# PIC32MZ2048EFM144 register map
Registers are 32-bit, access not given, reset 0x0 unless marked. A register's access mark holds for its fields unless they carry their own. Offsets are from the block's base; [hi:lo] are bit positions; {n}, {i} and the like mark numbered series; 'fields as' and 'values as' point back to an identical list.

## CFG — CFG peripheral
Base 0xBF800000
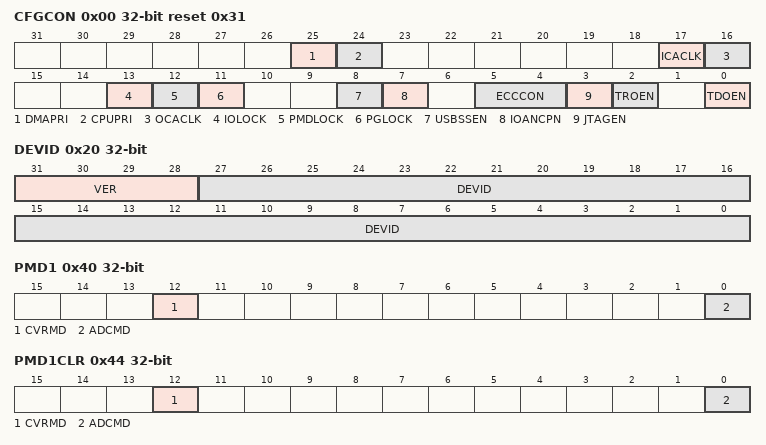
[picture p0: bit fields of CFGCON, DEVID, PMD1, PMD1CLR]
0x00 CFGCON reset 0x31
  [25] DMAPRI, [24] CPUPRI, [17] ICACLK, [16] OCACLK, [13] IOLOCK, [12] PMDLOCK, [11] PGLOCK, [8] USBSSEN, [7] IOANCPN, [5:4] ECCCON, [3] JTAGEN, [2] TROEN, [0] TDOEN
0x20 DEVID
  [31:28] VER, [27:0] DEVID
0x30 SYSKEY
0x40 PMD1
  [12] CVRMD, [0] ADCMD
0x44 PMD1CLR
  [12] CVRMD, [0] ADCMD
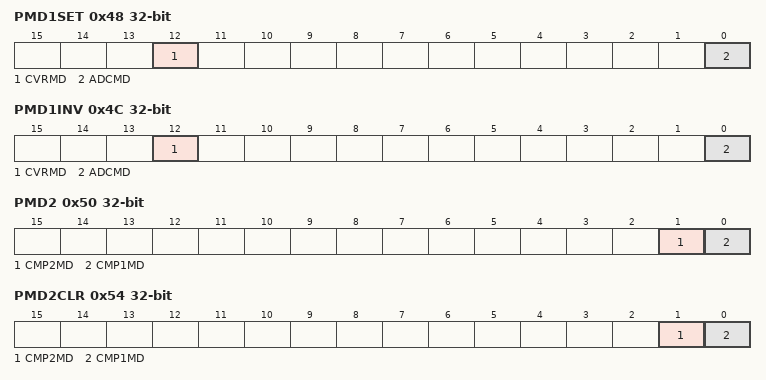
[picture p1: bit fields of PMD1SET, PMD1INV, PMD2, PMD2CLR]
0x48 PMD1SET
  [12] CVRMD, [0] ADCMD
0x4C PMD1INV
  [12] CVRMD, [0] ADCMD
0x50 PMD2
  [1] CMP2MD, [0] CMP1MD
0x54 PMD2CLR
  [1] CMP2MD, [0] CMP1MD
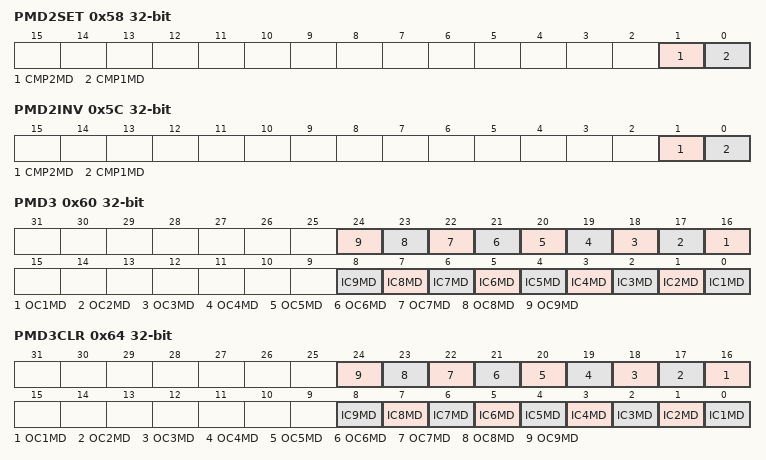
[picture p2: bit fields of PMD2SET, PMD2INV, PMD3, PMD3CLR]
0x58 PMD2SET
  [1] CMP2MD, [0] CMP1MD
0x5C PMD2INV
  [1] CMP2MD, [0] CMP1MD
0x60 PMD3
  [n+15] OC{n}MD (n=1..9), [n-1] IC{n}MD (n=1..9)
0x64 PMD3CLR
  [n+15] OC{n}MD (n=1..9), [n-1] IC{n}MD (n=1..9)
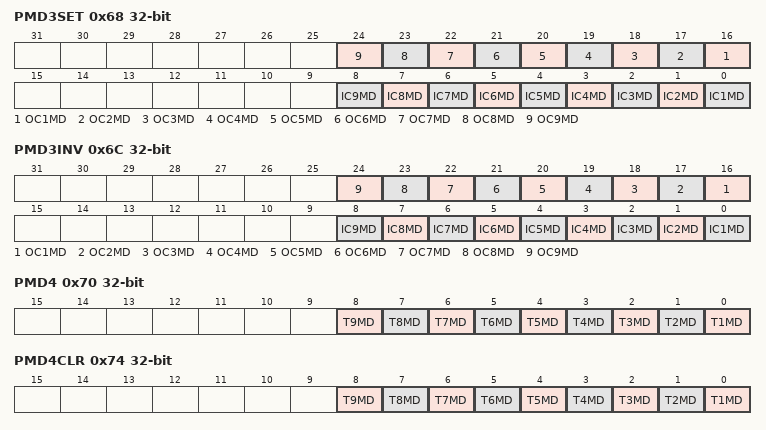
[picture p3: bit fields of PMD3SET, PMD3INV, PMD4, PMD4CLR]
0x68 PMD3SET
  [n+15] OC{n}MD (n=1..9), [n-1] IC{n}MD (n=1..9)
0x6C PMD3INV
  [n+15] OC{n}MD (n=1..9), [n-1] IC{n}MD (n=1..9)
0x70 PMD4
  [n-1] T{n}MD (n=1..9)
0x74 PMD4CLR
  [n-1] T{n}MD (n=1..9)
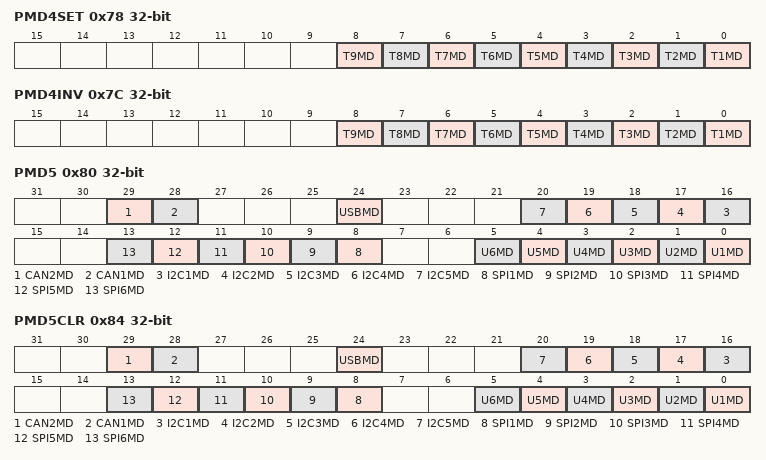
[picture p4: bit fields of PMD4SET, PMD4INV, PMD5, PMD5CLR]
0x78 PMD4SET
  [n-1] T{n}MD (n=1..9)
0x7C PMD4INV
  [n-1] T{n}MD (n=1..9)
0x80 PMD5
  [29] CAN2MD, [28] CAN1MD, [24] USBMD, [n+15] I2C{n}MD (n=1..5), [n+7] SPI{n}MD (n=1..6), [n-1] U{n}MD (n=1..6)
0x84 PMD5CLR
  fields as PMD5
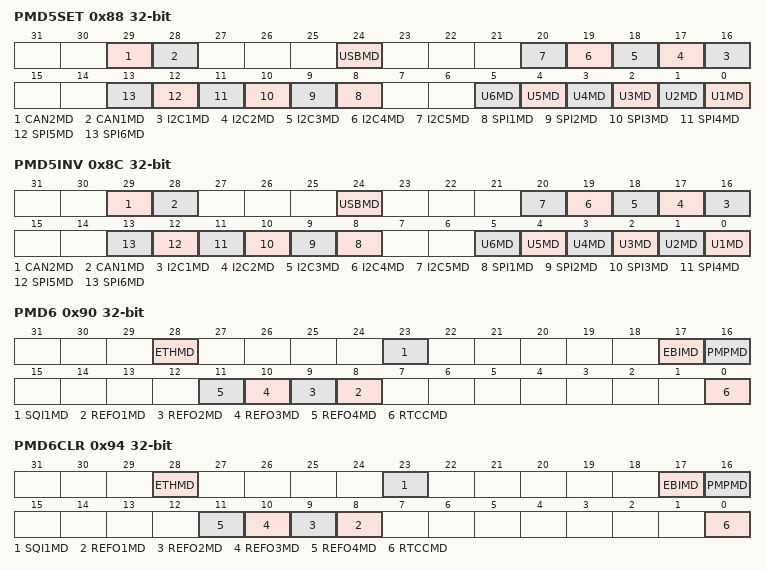
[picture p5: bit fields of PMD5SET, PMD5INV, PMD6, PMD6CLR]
0x88 PMD5SET
  fields as PMD5
0x8C PMD5INV
  fields as PMD5
0x90 PMD6
  [28] ETHMD, [23] SQI1MD, [17] EBIMD, [16] PMPMD, [n+7] REFO{n}MD (n=1..4), [0] RTCCMD
0x94 PMD6CLR
  fields as PMD6
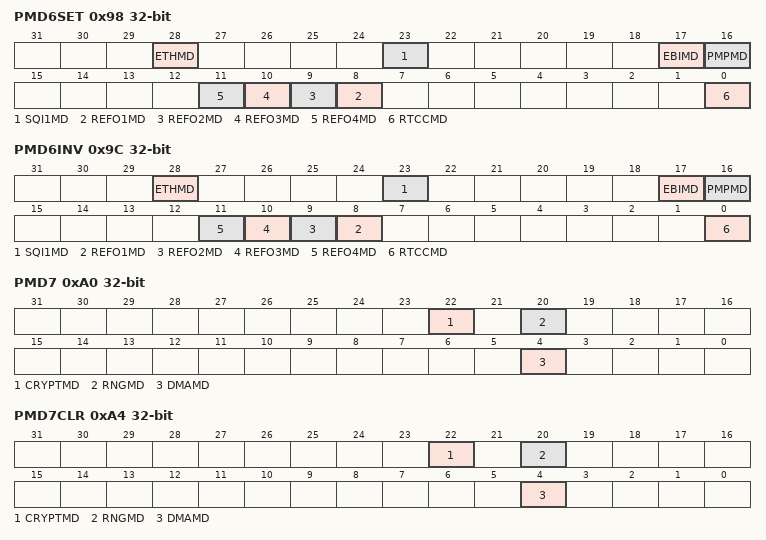
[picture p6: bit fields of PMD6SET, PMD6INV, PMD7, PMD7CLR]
0x98 PMD6SET
  fields as PMD6
0x9C PMD6INV
  fields as PMD6
0xA0 PMD7
  [22] CRYPTMD, [20] RNGMD, [4] DMAMD
0xA4 PMD7CLR
  [22] CRYPTMD, [20] RNGMD, [4] DMAMD
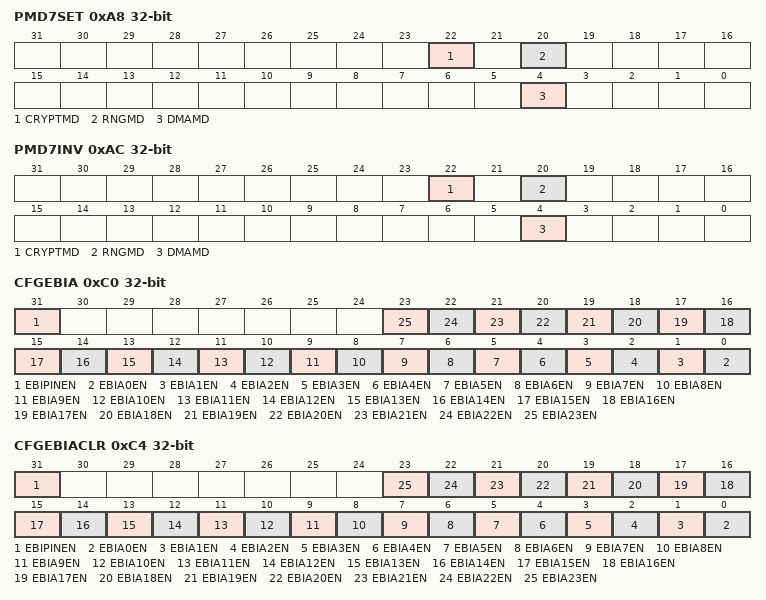
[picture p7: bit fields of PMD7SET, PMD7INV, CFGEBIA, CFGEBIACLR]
0xA8 PMD7SET
  [22] CRYPTMD, [20] RNGMD, [4] DMAMD
0xAC PMD7INV
  [22] CRYPTMD, [20] RNGMD, [4] DMAMD
0xC0 CFGEBIA
  [31] EBIPINEN, [n] EBIA{n}EN (n=0..23)
0xC4 CFGEBIACLR
  [31] EBIPINEN, [n] EBIA{n}EN (n=0..23)
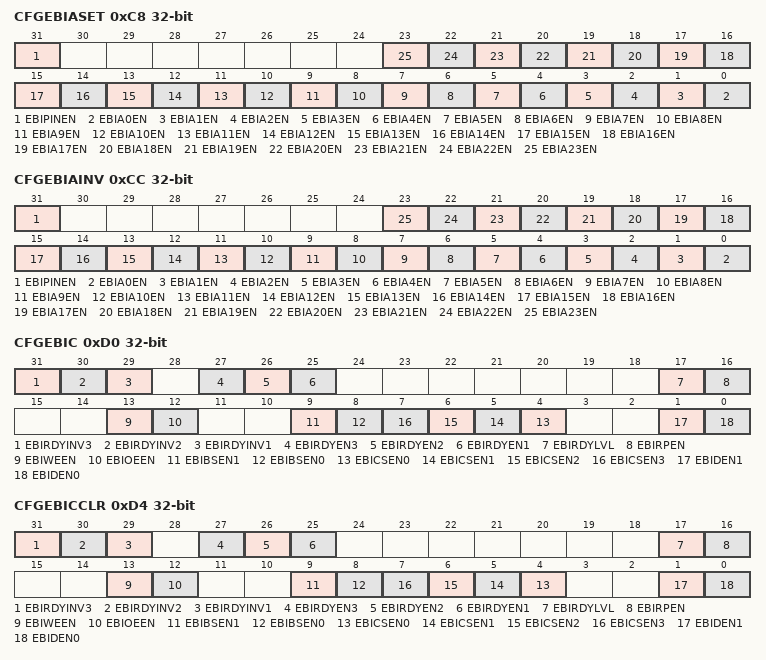
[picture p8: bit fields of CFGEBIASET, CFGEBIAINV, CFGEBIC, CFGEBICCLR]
0xC8 CFGEBIASET
  [31] EBIPINEN, [n] EBIA{n}EN (n=0..23)
0xCC CFGEBIAINV
  [31] EBIPINEN, [n] EBIA{n}EN (n=0..23)
0xD0 CFGEBIC
  [31] EBIRDYINV3, [30] EBIRDYINV2, [29] EBIRDYINV1, [27] EBIRDYEN3, [26] EBIRDYEN2, [25] EBIRDYEN1, [17] EBIRDYLVL, [16] EBIRPEN, [13] EBIWEEN, [12] EBIOEEN, [9] EBIBSEN1, [8] EBIBSEN0, [n+4] EBICSEN{n} (n=0..3), [1] EBIDEN1, [0] EBIDEN0
0xD4 CFGEBICCLR
  fields as CFGEBIC
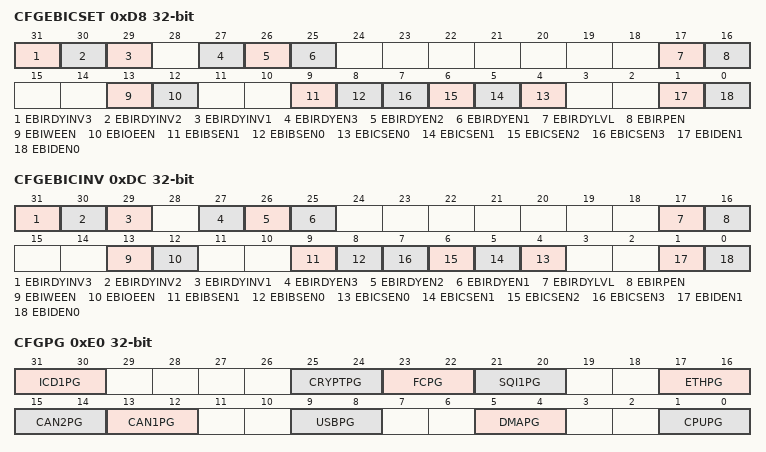
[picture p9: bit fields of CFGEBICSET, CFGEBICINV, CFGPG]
0xD8 CFGEBICSET
  fields as CFGEBIC
0xDC CFGEBICINV
  fields as CFGEBIC
0xE0 CFGPG
  [31:30] ICD1PG, [25:24] CRYPTPG, [23:22] FCPG, [21:20] SQI1PG, [17:16] ETHPG, [15:14] CAN2PG, [13:12] CAN1PG, [9:8] USBPG, [5:4] DMAPG, [1:0] CPUPG

## NVM — NVM peripheral
Base 0xBF800600
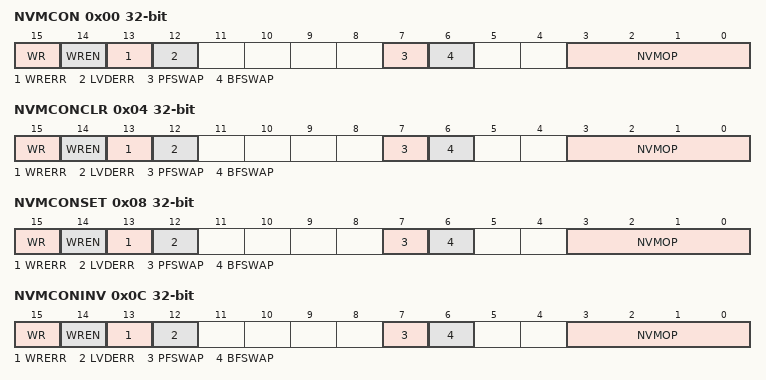
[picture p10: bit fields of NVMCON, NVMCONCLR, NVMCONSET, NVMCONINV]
0x00 NVMCON
  [15] WR, [14] WREN, [13] WRERR, [12] LVDERR, [7] PFSWAP, [6] BFSWAP, [3:0] NVMOP
0x04 NVMCONCLR
  fields as NVMCON
0x08 NVMCONSET
  fields as NVMCON
0x0C NVMCONINV
  fields as NVMCON
0x10 NVMKEY
0x20 NVMADDR
0x24 NVMADDRCLR
  [31:0] NVMADDR
0x28 NVMADDRSET
  [31:0] NVMADDR
0x2C NVMADDRINV
  [31:0] NVMADDR
{0x30+0x10*i} NVMDATA{i} (i=0..3)
{0x34+0x10*i} NVMDATA{i}CLR (i=0..3)
  [31:0] NVMDATA{i}
{0x38+0x10*i} NVMDATA{i}SET (i=0..3)
  [31:0] NVMDATA{i}
{0x3C+0x10*i} NVMDATA{i}INV (i=0..3)
  [31:0] NVMDATA{i}
0x70 NVMSRCADDR
0x74 NVMSRCADDRCLR
  [31:0] NVMSRCADDR
0x78 NVMSRCADDRSET
  [31:0] NVMSRCADDR
0x7C NVMSRCADDRINV
  [31:0] NVMSRCADDR
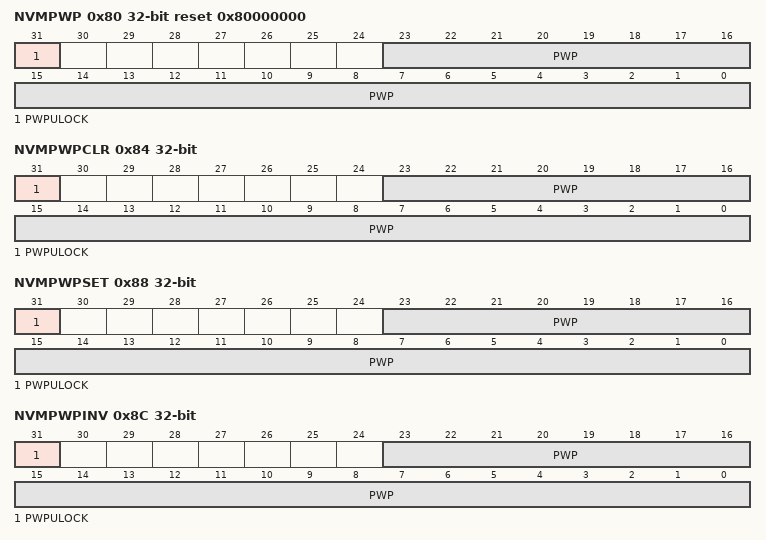
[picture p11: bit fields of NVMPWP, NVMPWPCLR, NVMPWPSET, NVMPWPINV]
0x80 NVMPWP reset 0x80000000
  [31] PWPULOCK, [23:0] PWP
0x84 NVMPWPCLR
  [31] PWPULOCK, [23:0] PWP
0x88 NVMPWPSET
  [31] PWPULOCK, [23:0] PWP
0x8C NVMPWPINV
  [31] PWPULOCK, [23:0] PWP
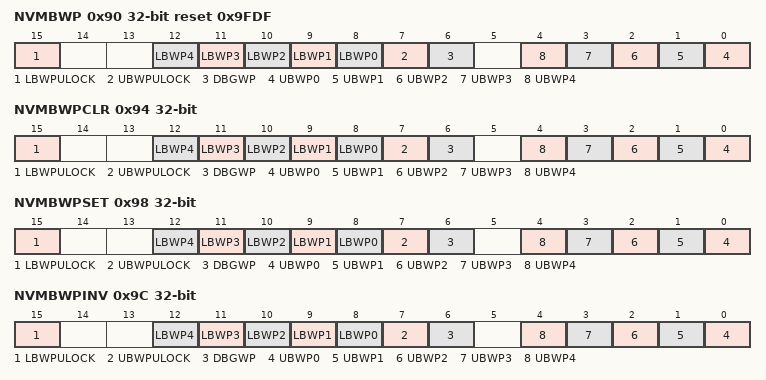
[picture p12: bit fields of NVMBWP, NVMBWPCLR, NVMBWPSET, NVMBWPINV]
0x90 NVMBWP reset 0x9FDF
  [15] LBWPULOCK, [n+8] LBWP{n} (n=0..4), [7] UBWPULOCK, [6] DBGWP, [n] UBWP{n} (n=0..4)
0x94 NVMBWPCLR
  fields as NVMBWP
0x98 NVMBWPSET
  fields as NVMBWP
0x9C NVMBWPINV
  fields as NVMBWP
0xA0 NVMCON2
  [7:6] SWAPLOCK
0xA4 NVMCON2CLR
  [7:6] SWAPLOCK
0xA8 NVMCON2SET
  [7:6] SWAPLOCK
0xAC NVMCON2INV
  [7:6] SWAPLOCK

## WDT — WDT peripheral
Base 0xBF800800
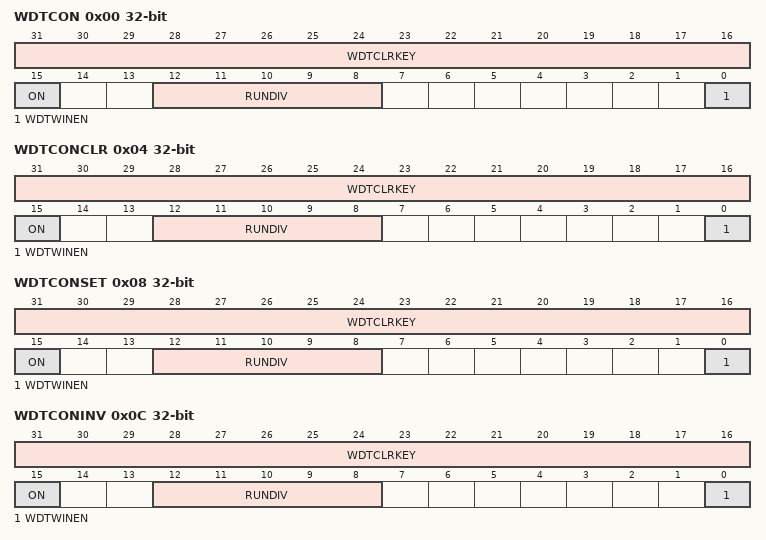
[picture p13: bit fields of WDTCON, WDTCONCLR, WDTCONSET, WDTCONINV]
0x00 WDTCON
  [31:16] WDTCLRKEY, [15] ON, [12:8] RUNDIV, [0] WDTWINEN
0x04 WDTCONCLR
  [31:16] WDTCLRKEY, [15] ON, [12:8] RUNDIV, [0] WDTWINEN
0x08 WDTCONSET
  [31:16] WDTCLRKEY, [15] ON, [12:8] RUNDIV, [0] WDTWINEN
0x0C WDTCONINV
  [31:16] WDTCLRKEY, [15] ON, [12:8] RUNDIV, [0] WDTWINEN
